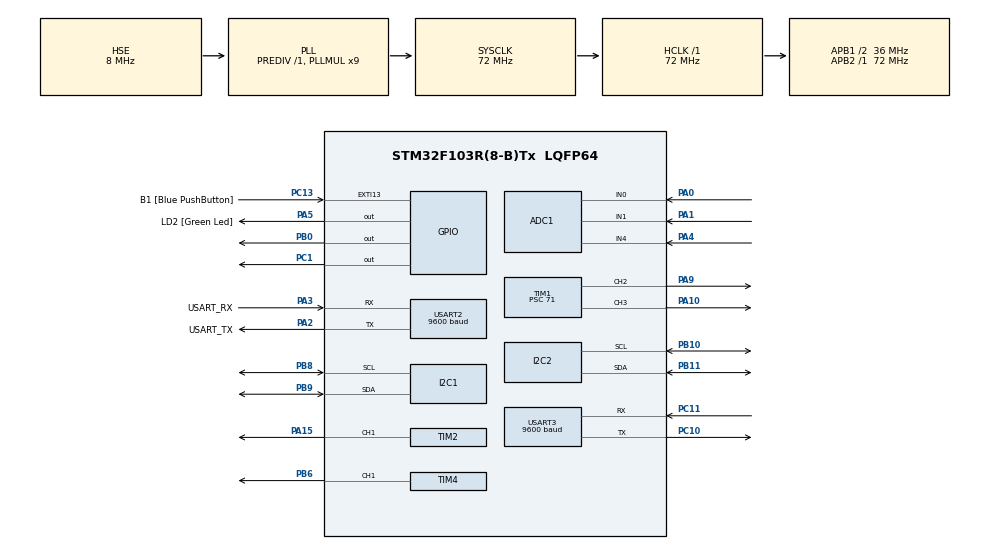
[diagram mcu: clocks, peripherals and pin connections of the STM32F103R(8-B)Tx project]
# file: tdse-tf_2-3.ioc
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ADC1.Channel-8\#ChannelRegularConversion=ADC_CHANNEL_1
ADC1.NbrOfConversionFlag=1
ADC1.Rank-8\#ChannelRegularConversion=1
ADC1.SamplingTime-8\#ChannelRegularConversion=ADC_SAMPLETIME_1CYCLE_5
ADC1.master=1
Dma.I2C1_RX.2.Direction=DMA_PERIPH_TO_MEMORY
Dma.I2C1_RX.2.Instance=DMA1_Channel7
Dma.I2C1_RX.2.MemDataAlignment=DMA_MDATAALIGN_BYTE
Dma.I2C1_RX.2.MemInc=DMA_MINC_ENABLE
Dma.I2C1_RX.2.Mode=DMA_NORMAL
Dma.I2C1_RX.2.PeriphDataAlignment=DMA_PDATAALIGN_BYTE
Dma.I2C1_RX.2.PeriphInc=DMA_PINC_DISABLE
Dma.I2C1_RX.2.Priority=DMA_PRIORITY_LOW
Dma.Request0=USART2_RX
Dma.Request1=USART3_RX
Dma.Request2=I2C1_RX
Dma.USART2_RX.0.Direction=DMA_PERIPH_TO_MEMORY
Dma.USART2_RX.0.Instance=DMA1_Channel6
Dma.USART2_RX.0.MemDataAlignment=DMA_MDATAALIGN_BYTE
Dma.USART2_RX.0.MemInc=DMA_MINC_ENABLE
Dma.USART2_RX.0.Mode=DMA_CIRCULAR
Dma.USART2_RX.0.PeriphDataAlignment=DMA_PDATAALIGN_BYTE
Dma.USART2_RX.0.PeriphInc=DMA_PINC_DISABLE
Dma.USART2_RX.0.Priority=DMA_PRIORITY_HIGH
Dma.USART3_RX.1.Direction=DMA_PERIPH_TO_MEMORY
Dma.USART3_RX.1.Instance=DMA1_Channel3
Dma.USART3_RX.1.MemDataAlignment=DMA_MDATAALIGN_BYTE
Dma.USART3_RX.1.MemInc=DMA_MINC_ENABLE
Dma.USART3_RX.1.Mode=DMA_CIRCULAR
Dma.USART3_RX.1.PeriphDataAlignment=DMA_PDATAALIGN_BYTE
Dma.USART3_RX.1.PeriphInc=DMA_PINC_DISABLE
Dma.USART3_RX.1.Priority=DMA_PRIORITY_LOW
Mcu.Family=STM32F1
Mcu.Name=STM32F103R(8-B)Tx
Mcu.Package=LQFP64
NVIC.ADC1_2_IRQn=true\:0\:0\:false\:false\:true\:true\:true\:true
NVIC.DMA1_Channel3_IRQn=true\:0\:0\:false\:false\:true\:false\:true\:true
NVIC.DMA1_Channel6_IRQn=true\:0\:0\:false\:false\:true\:false\:true\:true
NVIC.DMA1_Channel7_IRQn=true\:0\:0\:false\:false\:true\:false\:true\:true
NVIC.EXTI15_10_IRQn=true\:0\:0\:false\:false\:true\:true\:true\:true
NVIC.I2C1_ER_IRQn=true\:0\:0\:false\:false\:true\:true\:true\:true
NVIC.I2C1_EV_IRQn=true\:0\:0\:false\:false\:true\:true\:true\:true
NVIC.I2C2_ER_IRQn=true\:0\:0\:false\:false\:true\:true\:true\:true
NVIC.I2C2_EV_IRQn=true\:0\:0\:false\:false\:true\:true\:true\:true
NVIC.PriorityGroup=NVIC_PRIORITYGROUP_4
NVIC.TIM3_IRQn=true\:0\:0\:false\:false\:true\:true\:true\:true
NVIC.TIM4_IRQn=true\:0\:0\:false\:false\:true\:true\:true\:true
NVIC.USART2_IRQn=true\:0\:0\:false\:false\:true\:true\:true\:true
NVIC.USART3_IRQn=true\:0\:0\:false\:false\:true\:true\:true\:true
PA0-WKUP.Signal=ADCx_IN0
PA1.Signal=ADCx_IN1
PA10.Signal=S_TIM1_CH3
PA13.GPIO_Label=TMS
PA13.Mode=Serial_Wire
PA13.Signal=SYS_JTMS-SWDIO
PA14.GPIO_Label=TCK
PA14.Mode=Serial_Wire
PA14.Signal=SYS_JTCK-SWCLK
PA15.GPIO_ModeDefaultPP=GPIO_MODE_AF_OD
PA15.Signal=S_TIM2_CH1_ETR
PA2.GPIO_Label=USART_TX
PA2.GPIO_Mode=GPIO_MODE_AF_PP
PA2.GPIO_PuPd=GPIO_NOPULL
PA2.GPIO_Speed=GPIO_SPEED_FREQ_LOW
PA2.Mode=Asynchronous
PA2.Signal=USART2_TX
PA3.GPIO_Label=USART_RX
PA3.GPIO_Mode=GPIO_MODE_INPUT
PA3.GPIO_PuPd=GPIO_NOPULL
PA3.GPIO_Speed=GPIO_SPEED_FREQ_LOW
PA3.Mode=Asynchronous
PA3.Signal=USART2_RX
PA4.Signal=ADCx_IN4
PA5.GPIO_Label=LD2 [Green Led]
PA5.GPIO_ModeDefaultOutputPP=GPIO_MODE_OUTPUT_PP
PA5.GPIO_PuPd=GPIO_NOPULL
PA5.GPIO_Speed=GPIO_SPEED_FREQ_LOW
PA5.Signal=GPIO_Output
PA9.Signal=S_TIM1_CH2
PB0.GPIO_PuPd=GPIO_NOPULL
PB0.PinState=GPIO_PIN_SET
PB0.Signal=GPIO_Output
PB10.Mode=I2C
PB10.Signal=I2C2_SCL
PB11.Mode=I2C
PB11.Signal=I2C2_SDA
PB3.GPIO_Label=SWO
PB3.Signal=SYS_JTDO-TRACESWO
PB6.Signal=S_TIM4_CH1
PB8.Mode=I2C
PB8.Signal=I2C1_SCL
PB9.Mode=I2C
PB9.Signal=I2C1_SDA
PC1.GPIO_PuPd=GPIO_NOPULL
PC1.PinState=GPIO_PIN_SET
PC1.Signal=GPIO_Output
PC10.Mode=Asynchronous
PC10.Signal=USART3_TX
PC11.Mode=Asynchronous
PC11.Signal=USART3_RX
PC13-TAMPER-RTC.GPIO_Label=B1 [Blue PushButton]
PC13-TAMPER-RTC.GPIO_PuPd=GPIO_NOPULL
PC13-TAMPER-RTC.Signal=GPXTI13
PC14-OSC32_IN.Mode=LSE-External-Oscillator
PC14-OSC32_IN.Signal=RCC_OSC32_IN
PC15-OSC32_OUT.Mode=LSE-External-Oscillator
PC15-OSC32_OUT.Signal=RCC_OSC32_OUT
PD0-OSC_IN.Mode=HSE-External-Oscillator
PD0-OSC_IN.Signal=RCC_OSC_IN
PD1-OSC_OUT.Mode=HSE-External-Oscillator
PD1-OSC_OUT.Signal=RCC_OSC_OUT
ProjectManager.HeapSize=0x200
ProjectManager.StackSize=0x400
ProjectManager.TargetToolchain=STM32CubeIDE
RCC.ADCPresc=RCC_ADCPCLK2_DIV6
RCC.AHBFreq_Value=72000000
RCC.APB1CLKDivider=RCC_HCLK_DIV2
RCC.APB1Freq_Value=36000000
RCC.APB1TimFreq_Value=72000000
RCC.APB2Freq_Value=72000000
RCC.APB2TimFreq_Value=72000000
RCC.HCLKFreq_Value=72000000
RCC.PLLMUL=RCC_PLL_MUL9
RCC.PLLSourceVirtual=RCC_PLLSOURCE_HSE
RCC.RTCClockSelection=RCC_RTCCLKSOURCE_LSE
RCC.SYSCLKFreq_VALUE=72000000
RCC.SYSCLKSource=RCC_SYSCLKSOURCE_PLLCLK
RCC.USBFreq_Value=72000000
SH.ADCx_IN0.0=ADC1_IN0,IN0
SH.ADCx_IN1.0=ADC1_IN1,IN1
SH.ADCx_IN4.0=ADC1_IN4,IN4
SH.S_TIM1_CH2.0=TIM1_CH2,PWM Generation2 CH2
SH.S_TIM1_CH3.0=TIM1_CH3,PWM Generation3 CH3
SH.S_TIM2_CH1_ETR.0=TIM2_CH1,PWM Generation1 CH1
SH.S_TIM4_CH1.0=TIM4_CH1,PWM Generation1 CH1
TIM1.Channel-PWM\ Generation2\ CH2=TIM_CHANNEL_2
TIM1.Channel-PWM\ Generation3\ CH3=TIM_CHANNEL_3
TIM1.Period=999
TIM1.Prescaler=71
TIM2.Channel-PWM\ Generation1\ CH1=TIM_CHANNEL_1
TIM2.Period=2879
TIM2.Pulse-PWM\ Generation1\ CH1=1440
TIM3.Period=999
TIM3.Prescaler=799
TIM4.Channel-PWM\ Generation1\ CH1=TIM_CHANNEL_1
TIM4.Period=999
TIM4.Prescaler=71
USART2.BaudRate=9600
USART2.VirtualMode=VM_ASYNC
USART3.BaudRate=9600
USART3.VirtualMode=VM_ASYNC
VP_TIM1_VS_ClockSourceINT.Mode=Internal
VP_TIM2_VS_ClockSourceINT.Mode=Internal
VP_TIM3_VS_ClockSourceINT.Mode=Internal
VP_TIM4_VS_ClockSourceINT.Mode=Internal
board=NUCLEO-F103RB

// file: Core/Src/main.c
/* USER CODE BEGIN Header */
/**
  ******************************************************************************
  * @file           : main.c
  * @brief          : Main program body
  ******************************************************************************
  * @attention
  *
  * Copyright (c) 2025 STMicroelectronics.
  * All rights reserved.
  *
  * This software is licensed under terms that can be found in the LICENSE file
  * in the root directory of this software component.
  * If no LICENSE file comes with this software, it is provided AS-IS.
  *
  ******************************************************************************
  */
/* USER CODE END Header */
#include "main.h"

/* USER CODE BEGIN Includes */

/* Application includes. */
#include "logger.h"
#include "app.h"

/* USER CODE END Includes */

ADC_HandleTypeDef hadc1;

I2C_HandleTypeDef hi2c1;
I2C_HandleTypeDef hi2c2;
DMA_HandleTypeDef hdma_i2c1_rx;

TIM_HandleTypeDef htim1;
TIM_HandleTypeDef htim2;
TIM_HandleTypeDef htim3;
TIM_HandleTypeDef htim4;

UART_HandleTypeDef huart2;
UART_HandleTypeDef huart3;
DMA_HandleTypeDef hdma_usart2_rx;
DMA_HandleTypeDef hdma_usart3_rx;

void SystemClock_Config(void);
static void MX_GPIO_Init(void);
static void MX_DMA_Init(void);
static void MX_USART2_UART_Init(void);
static void MX_ADC1_Init(void);
static void MX_TIM1_Init(void);
static void MX_TIM4_Init(void);
static void MX_USART3_UART_Init(void);
static void MX_I2C1_Init(void);
static void MX_TIM3_Init(void);
static void MX_TIM2_Init(void);
static void MX_I2C2_Init(void);

/* USER CODE BEGIN 0 */
#if (1 == LOGGER_CONFIG_USE_SEMIHOSTING)

extern void initialise_monitor_handles(void);

#endif

/* USER CODE END 0 */

int main(void)
{

  /* USER CODE BEGIN 1 */
  #if (1 == LOGGER_CONFIG_USE_SEMIHOSTING)

  initialise_monitor_handles();

  #endif

  /* USER CODE END 1 */

  /* MCU Configuration--------------------------------------------------------*/

  /* Reset of all peripherals, Initializes the Flash interface and the Systick. */
  HAL_Init();

  /* Configure the system clock */
  SystemClock_Config();

  /* Initialize all configured peripherals */
  MX_GPIO_Init();
  MX_DMA_Init();
  MX_USART2_UART_Init();
  MX_ADC1_Init();
  MX_TIM1_Init();
  MX_TIM4_Init();
  MX_USART3_UART_Init();
  MX_I2C1_Init();
  MX_TIM3_Init();
  MX_TIM2_Init();
  MX_I2C2_Init();
  /* USER CODE BEGIN 2 */
  HAL_TIM_Base_Start_IT(&htim3);
  /* Application Init */
  app_init();

  /* USER CODE END 2 */

  /* Infinite loop */
  while (1)
  {

    /* USER CODE BEGIN 3 */

    /* Application Update */
    app_update();
  }
  /* USER CODE END 3 */
}

void SystemClock_Config(void)
{
  RCC_OscInitTypeDef RCC_OscInitStruct = {0};
  RCC_ClkInitTypeDef RCC_ClkInitStruct = {0};
  RCC_PeriphCLKInitTypeDef PeriphClkInit = {0};

  /** Initializes the RCC Oscillators according to the specified parameters
  * in the RCC_OscInitTypeDef structure.
  */
  RCC_OscInitStruct.OscillatorType = RCC_OSCILLATORTYPE_HSE;
  RCC_OscInitStruct.HSEState = RCC_HSE_ON;
  RCC_OscInitStruct.HSEPredivValue = RCC_HSE_PREDIV_DIV1;
  RCC_OscInitStruct.HSIState = RCC_HSI_ON;
  RCC_OscInitStruct.PLL.PLLState = RCC_PLL_ON;
  RCC_OscInitStruct.PLL.PLLSource = RCC_PLLSOURCE_HSE;
  RCC_OscInitStruct.PLL.PLLMUL = RCC_PLL_MUL9;
  if (HAL_RCC_OscConfig(&RCC_OscInitStruct) != HAL_OK)
  {
    Error_Handler();
  }

  /** Initializes the CPU, AHB and APB buses clocks
  */
  RCC_ClkInitStruct.ClockType = RCC_CLOCKTYPE_HCLK|RCC_CLOCKTYPE_SYSCLK
                              |RCC_CLOCKTYPE_PCLK1|RCC_CLOCKTYPE_PCLK2;
  RCC_ClkInitStruct.SYSCLKSource = RCC_SYSCLKSOURCE_PLLCLK;
  RCC_ClkInitStruct.AHBCLKDivider = RCC_SYSCLK_DIV1;
  RCC_ClkInitStruct.APB1CLKDivider = RCC_HCLK_DIV2;
  RCC_ClkInitStruct.APB2CLKDivider = RCC_HCLK_DIV1;

  if (HAL_RCC_ClockConfig(&RCC_ClkInitStruct, FLASH_LATENCY_2) != HAL_OK)
  {
    Error_Handler();
  }
  PeriphClkInit.PeriphClockSelection = RCC_PERIPHCLK_ADC;
  PeriphClkInit.AdcClockSelection = RCC_ADCPCLK2_DIV6;
  if (HAL_RCCEx_PeriphCLKConfig(&PeriphClkInit) != HAL_OK)
  {
    Error_Handler();
  }
}

static void MX_ADC1_Init(void)
{

  ADC_ChannelConfTypeDef sConfig = {0};

  /** Common config
  */
  hadc1.Instance = ADC1;
  hadc1.Init.ScanConvMode = ADC_SCAN_DISABLE;
  hadc1.Init.ContinuousConvMode = DISABLE;
  hadc1.Init.DiscontinuousConvMode = DISABLE;
  hadc1.Init.ExternalTrigConv = ADC_SOFTWARE_START;
  hadc1.Init.DataAlign = ADC_DATAALIGN_RIGHT;
  hadc1.Init.NbrOfConversion = 1;
  if (HAL_ADC_Init(&hadc1) != HAL_OK)
  {
    Error_Handler();
  }

  /** Configure Regular Channel
  */
  sConfig.Channel = ADC_CHANNEL_1;
  sConfig.Rank = ADC_REGULAR_RANK_1;
  sConfig.SamplingTime = ADC_SAMPLETIME_1CYCLE_5;
  if (HAL_ADC_ConfigChannel(&hadc1, &sConfig) != HAL_OK)
  {
    Error_Handler();
  }

}

static void MX_I2C1_Init(void)
{

  hi2c1.Instance = I2C1;
  hi2c1.Init.ClockSpeed = 100000;
  hi2c1.Init.DutyCycle = I2C_DUTYCYCLE_2;
  hi2c1.Init.OwnAddress1 = 0;
  hi2c1.Init.AddressingMode = I2C_ADDRESSINGMODE_7BIT;
  hi2c1.Init.DualAddressMode = I2C_DUALADDRESS_DISABLE;
  hi2c1.Init.OwnAddress2 = 0;
  hi2c1.Init.GeneralCallMode = I2C_GENERALCALL_DISABLE;
  hi2c1.Init.NoStretchMode = I2C_NOSTRETCH_DISABLE;
  if (HAL_I2C_Init(&hi2c1) != HAL_OK)
  {
    Error_Handler();
  }

}

static void MX_I2C2_Init(void)
{

  hi2c2.Instance = I2C2;
  hi2c2.Init.ClockSpeed = 100000;
  hi2c2.Init.DutyCycle = I2C_DUTYCYCLE_2;
  hi2c2.Init.OwnAddress1 = 0;
  hi2c2.Init.AddressingMode = I2C_ADDRESSINGMODE_7BIT;
  hi2c2.Init.DualAddressMode = I2C_DUALADDRESS_DISABLE;
  hi2c2.Init.OwnAddress2 = 0;
  hi2c2.Init.GeneralCallMode = I2C_GENERALCALL_DISABLE;
  hi2c2.Init.NoStretchMode = I2C_NOSTRETCH_DISABLE;
  if (HAL_I2C_Init(&hi2c2) != HAL_OK)
  {
    Error_Handler();
  }

}

static void MX_TIM1_Init(void)
{

  TIM_ClockConfigTypeDef sClockSourceConfig = {0};
  TIM_MasterConfigTypeDef sMasterConfig = {0};
  TIM_OC_InitTypeDef sConfigOC = {0};
  TIM_BreakDeadTimeConfigTypeDef sBreakDeadTimeConfig = {0};

  htim1.Instance = TIM1;
  htim1.Init.Prescaler = 71;
  htim1.Init.CounterMode = TIM_COUNTERMODE_UP;
  htim1.Init.Period = 999;
  htim1.Init.ClockDivision = TIM_CLOCKDIVISION_DIV1;
  htim1.Init.RepetitionCounter = 0;
  htim1.Init.AutoReloadPreload = TIM_AUTORELOAD_PRELOAD_DISABLE;
  if (HAL_TIM_Base_Init(&htim1) != HAL_OK)
  {
    Error_Handler();
  }
  sClockSourceConfig.ClockSource = TIM_CLOCKSOURCE_INTERNAL;
  if (HAL_TIM_ConfigClockSource(&htim1, &sClockSourceConfig) != HAL_OK)
  {
    Error_Handler();
  }
  if (HAL_TIM_PWM_Init(&htim1) != HAL_OK)
  {
    Error_Handler();
  }
  sMasterConfig.MasterOutputTrigger = TIM_TRGO_RESET;
  sMasterConfig.MasterSlaveMode = TIM_MASTERSLAVEMODE_DISABLE;
  if (HAL_TIMEx_MasterConfigSynchronization(&htim1, &sMasterConfig) != HAL_OK)
  {
    Error_Handler();
  }
  sConfigOC.OCMode = TIM_OCMODE_PWM1;
  sConfigOC.Pulse = 0;
  sConfigOC.OCPolarity = TIM_OCPOLARITY_HIGH;
  sConfigOC.OCNPolarity = TIM_OCNPOLARITY_HIGH;
  sConfigOC.OCFastMode = TIM_OCFAST_DISABLE;
  sConfigOC.OCIdleState = TIM_OCIDLESTATE_RESET;
  sConfigOC.OCNIdleState = TIM_OCNIDLESTATE_RESET;
  if (HAL_TIM_PWM_ConfigChannel(&htim1, &sConfigOC, TIM_CHANNEL_2) != HAL_OK)
  {
    Error_Handler();
  }
  if (HAL_TIM_PWM_ConfigChannel(&htim1, &sConfigOC, TIM_CHANNEL_3) != HAL_OK)
  {
    Error_Handler();
  }
  sBreakDeadTimeConfig.OffStateRunMode = TIM_OSSR_DISABLE;
  sBreakDeadTimeConfig.OffStateIDLEMode = TIM_OSSI_DISABLE;
  sBreakDeadTimeConfig.LockLevel = TIM_LOCKLEVEL_OFF;
  sBreakDeadTimeConfig.DeadTime = 0;
  sBreakDeadTimeConfig.BreakState = TIM_BREAK_DISABLE;
  sBreakDeadTimeConfig.BreakPolarity = TIM_BREAKPOLARITY_HIGH;
  sBreakDeadTimeConfig.AutomaticOutput = TIM_AUTOMATICOUTPUT_DISABLE;
  if (HAL_TIMEx_ConfigBreakDeadTime(&htim1, &sBreakDeadTimeConfig) != HAL_OK)
  {
    Error_Handler();
  }
  HAL_TIM_MspPostInit(&htim1);

}

static void MX_TIM2_Init(void)
{

  TIM_ClockConfigTypeDef sClockSourceConfig = {0};
  TIM_MasterConfigTypeDef sMasterConfig = {0};
  TIM_OC_InitTypeDef sConfigOC = {0};

  htim2.Instance = TIM2;
  htim2.Init.Prescaler = 0;
  htim2.Init.CounterMode = TIM_COUNTERMODE_UP;
  htim2.Init.Period = 2879;
  htim2.Init.ClockDivision = TIM_CLOCKDIVISION_DIV1;
  htim2.Init.AutoReloadPreload = TIM_AUTORELOAD_PRELOAD_DISABLE;
  if (HAL_TIM_Base_Init(&htim2) != HAL_OK)
  {
    Error_Handler();
  }
  sClockSourceConfig.ClockSource = TIM_CLOCKSOURCE_INTERNAL;
  if (HAL_TIM_ConfigClockSource(&htim2, &sClockSourceConfig) != HAL_OK)
  {
    Error_Handler();
  }
  if (HAL_TIM_PWM_Init(&htim2) != HAL_OK)
  {
    Error_Handler();
  }
  sMasterConfig.MasterOutputTrigger = TIM_TRGO_RESET;
  sMasterConfig.MasterSlaveMode = TIM_MASTERSLAVEMODE_DISABLE;
  if (HAL_TIMEx_MasterConfigSynchronization(&htim2, &sMasterConfig) != HAL_OK)
  {
    Error_Handler();
  }
  sConfigOC.OCMode = TIM_OCMODE_PWM1;
  sConfigOC.Pulse = 1440;
  sConfigOC.OCPolarity = TIM_OCPOLARITY_HIGH;
  sConfigOC.OCFastMode = TIM_OCFAST_DISABLE;
  if (HAL_TIM_PWM_ConfigChannel(&htim2, &sConfigOC, TIM_CHANNEL_1) != HAL_OK)
  {
    Error_Handler();
  }
  HAL_TIM_MspPostInit(&htim2);

}

static void MX_TIM3_Init(void)
{

  TIM_ClockConfigTypeDef sClockSourceConfig = {0};
  TIM_MasterConfigTypeDef sMasterConfig = {0};

  htim3.Instance = TIM3;
  htim3.Init.Prescaler = 799;
  htim3.Init.CounterMode = TIM_COUNTERMODE_UP;
  htim3.Init.Period = 999;
  htim3.Init.ClockDivision = TIM_CLOCKDIVISION_DIV1;
  htim3.Init.AutoReloadPreload = TIM_AUTORELOAD_PRELOAD_DISABLE;
  if (HAL_TIM_Base_Init(&htim3) != HAL_OK)
  {
    Error_Handler();
  }
  sClockSourceConfig.ClockSource = TIM_CLOCKSOURCE_INTERNAL;
  if (HAL_TIM_ConfigClockSource(&htim3, &sClockSourceConfig) != HAL_OK)
  {
    Error_Handler();
  }
  sMasterConfig.MasterOutputTrigger = TIM_TRGO_RESET;
  sMasterConfig.MasterSlaveMode = TIM_MASTERSLAVEMODE_DISABLE;
  if (HAL_TIMEx_MasterConfigSynchronization(&htim3, &sMasterConfig) != HAL_OK)
  {
    Error_Handler();
  }

}

static void MX_TIM4_Init(void)
{

  TIM_ClockConfigTypeDef sClockSourceConfig = {0};
  TIM_MasterConfigTypeDef sMasterConfig = {0};
  TIM_OC_InitTypeDef sConfigOC = {0};

  htim4.Instance = TIM4;
  htim4.Init.Prescaler = 71;
  htim4.Init.CounterMode = TIM_COUNTERMODE_UP;
  htim4.Init.Period = 999;
  htim4.Init.ClockDivision = TIM_CLOCKDIVISION_DIV1;
  htim4.Init.AutoReloadPreload = TIM_AUTORELOAD_PRELOAD_DISABLE;
  if (HAL_TIM_Base_Init(&htim4) != HAL_OK)
  {
    Error_Handler();
  }
  sClockSourceConfig.ClockSource = TIM_CLOCKSOURCE_INTERNAL;
  if (HAL_TIM_ConfigClockSource(&htim4, &sClockSourceConfig) != HAL_OK)
  {
    Error_Handler();
  }
  if (HAL_TIM_PWM_Init(&htim4) != HAL_OK)
  {
    Error_Handler();
  }
  sMasterConfig.MasterOutputTrigger = TIM_TRGO_RESET;
  sMasterConfig.MasterSlaveMode = TIM_MASTERSLAVEMODE_DISABLE;
  if (HAL_TIMEx_MasterConfigSynchronization(&htim4, &sMasterConfig) != HAL_OK)
  {
    Error_Handler();
  }
  sConfigOC.OCMode = TIM_OCMODE_PWM1;
  sConfigOC.Pulse = 0;
  sConfigOC.OCPolarity = TIM_OCPOLARITY_HIGH;
  sConfigOC.OCFastMode = TIM_OCFAST_DISABLE;
  if (HAL_TIM_PWM_ConfigChannel(&htim4, &sConfigOC, TIM_CHANNEL_1) != HAL_OK)
  {
    Error_Handler();
  }
  HAL_TIM_MspPostInit(&htim4);

}

static void MX_USART2_UART_Init(void)
{

  huart2.Instance = USART2;
  huart2.Init.BaudRate = 9600;
  huart2.Init.WordLength = UART_WORDLENGTH_8B;
  huart2.Init.StopBits = UART_STOPBITS_1;
  huart2.Init.Parity = UART_PARITY_NONE;
  huart2.Init.Mode = UART_MODE_TX_RX;
  huart2.Init.HwFlowCtl = UART_HWCONTROL_NONE;
  huart2.Init.OverSampling = UART_OVERSAMPLING_16;
  if (HAL_UART_Init(&huart2) != HAL_OK)
  {
    Error_Handler();
  }

}

static void MX_USART3_UART_Init(void)
{

  huart3.Instance = USART3;
  huart3.Init.BaudRate = 9600;
  huart3.Init.WordLength = UART_WORDLENGTH_8B;
  huart3.Init.StopBits = UART_STOPBITS_1;
  huart3.Init.Parity = UART_PARITY_NONE;
  huart3.Init.Mode = UART_MODE_TX_RX;
  huart3.Init.HwFlowCtl = UART_HWCONTROL_NONE;
  huart3.Init.OverSampling = UART_OVERSAMPLING_16;
  if (HAL_UART_Init(&huart3) != HAL_OK)
  {
    Error_Handler();
  }

}

static void MX_DMA_Init(void)
{

  /* DMA controller clock enable */
  __HAL_RCC_DMA1_CLK_ENABLE();

  /* DMA interrupt init */
  /* DMA1_Channel3_IRQn interrupt configuration */
  HAL_NVIC_SetPriority(DMA1_Channel3_IRQn, 0, 0);
  HAL_NVIC_EnableIRQ(DMA1_Channel3_IRQn);
  /* DMA1_Channel6_IRQn interrupt configuration */
  HAL_NVIC_SetPriority(DMA1_Channel6_IRQn, 0, 0);
  HAL_NVIC_EnableIRQ(DMA1_Channel6_IRQn);
  /* DMA1_Channel7_IRQn interrupt configuration */
  HAL_NVIC_SetPriority(DMA1_Channel7_IRQn, 0, 0);
  HAL_NVIC_EnableIRQ(DMA1_Channel7_IRQn);

}

static void MX_GPIO_Init(void)
{
  GPIO_InitTypeDef GPIO_InitStruct = {0};

  /* GPIO Ports Clock Enable */
  __HAL_RCC_GPIOC_CLK_ENABLE();
  __HAL_RCC_GPIOD_CLK_ENABLE();
  __HAL_RCC_GPIOA_CLK_ENABLE();
  __HAL_RCC_GPIOB_CLK_ENABLE();

  /*Configure GPIO pin Output Level */
  HAL_GPIO_WritePin(GPIOC, GPIO_PIN_1, GPIO_PIN_SET);

  /*Configure GPIO pin Output Level */
  HAL_GPIO_WritePin(LD2_GPIO_Port, LD2_Pin, GPIO_PIN_RESET);

  /*Configure GPIO pin Output Level */
  HAL_GPIO_WritePin(GPIOB, GPIO_PIN_0, GPIO_PIN_SET);

  /*Configure GPIO pin : B1_Pin */
  GPIO_InitStruct.Pin = B1_Pin;
  GPIO_InitStruct.Mode = GPIO_MODE_IT_RISING;
  GPIO_InitStruct.Pull = GPIO_NOPULL;
  HAL_GPIO_Init(B1_GPIO_Port, &GPIO_InitStruct);

  /*Configure GPIO pin : PC1 */
  GPIO_InitStruct.Pin = GPIO_PIN_1;
  GPIO_InitStruct.Mode = GPIO_MODE_OUTPUT_PP;
  GPIO_InitStruct.Pull = GPIO_NOPULL;
  GPIO_InitStruct.Speed = GPIO_SPEED_FREQ_LOW;
  HAL_GPIO_Init(GPIOC, &GPIO_InitStruct);

  /*Configure GPIO pin : LD2_Pin */
  GPIO_InitStruct.Pin = LD2_Pin;
  GPIO_InitStruct.Mode = GPIO_MODE_OUTPUT_PP;
  GPIO_InitStruct.Pull = GPIO_NOPULL;
  GPIO_InitStruct.Speed = GPIO_SPEED_FREQ_LOW;
  HAL_GPIO_Init(LD2_GPIO_Port, &GPIO_InitStruct);

  /*Configure GPIO pin : PB0 */
  GPIO_InitStruct.Pin = GPIO_PIN_0;
  GPIO_InitStruct.Mode = GPIO_MODE_OUTPUT_PP;
  GPIO_InitStruct.Pull = GPIO_NOPULL;
  GPIO_InitStruct.Speed = GPIO_SPEED_FREQ_LOW;
  HAL_GPIO_Init(GPIOB, &GPIO_InitStruct);

  /* EXTI interrupt init*/
  HAL_NVIC_SetPriority(EXTI15_10_IRQn, 0, 0);
  HAL_NVIC_EnableIRQ(EXTI15_10_IRQn);

}

void Error_Handler(void)
{
  __disable_irq();
  while (1)
  {
  }
}
